AUTOSAR XML (schema 4-2-2)
package /EB/SoftwareComponents
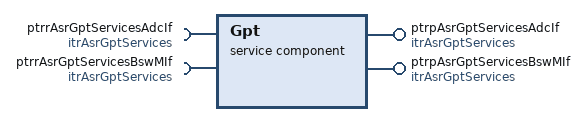
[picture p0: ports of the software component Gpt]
  service sw component type Gpt: category=ASR_Interfaces
    provide port ptrpAsrGptServicesAdcIf: provided-interface=itrAsrGptServices
    provide port ptrpAsrGptServicesBswMIf: provided-interface=itrAsrGptServices
    require port ptrrAsrGptServicesAdcIf: required-interface=itrAsrGptServices
    require port ptrrAsrGptServicesBswMIf: required-interface=itrAsrGptServices
    behavior Gpt_IB: handle-termination-and-restart=NO-SUPPORT
      external trigger occurred event trAdcIf_GPTOnTimer_Expiration: start-on-event=Gpt_InitChannel, trigger=ptrrAsrGptServicesAdcIf.AdcIf_GPTOnTimer_Expiration
      6 x runnable:
        Gpt_DisableNotification
        Gpt_EnableNotification: external-triggering-point=ptrpAsrGptServicesAdcIf.Gpt_EnableNotification
        Gpt_Init: external-triggering-point=ptrpAsrGptServicesAdcIf.Gpt_Init
        Gpt_InitChannel
        Gpt_StartTimer: external-triggering-point=ptrpAsrGptServicesAdcIf.Gpt_StartTimer
        Gpt_StopTimer
package /EB/TriggerInterfaces
  trigger interface itrAsrGptServices
    7 x trigger, all with trigger-period={cse-code=1000, cse-code-factor=0}:
      AdcIf_GPTOnTimer_Expiration
      BswM_Cyclic_10msTimer
      Gpt_DisableNotification
      Gpt_EnableNotification
      Gpt_Init
      Gpt_StartTimer
      Gpt_StopTimer
